# GAP8 register map
Vendor: GreenWaves Technologies SAS; Series: GAP8; File version: 1.3.1
CPU: other r1p0, little endian, MPU, no FPU, I-cache, DTCM, false interrupt priority bits
Registers are 32-bit, read-write, reset 0x0 unless marked. A register's access mark holds for its fields unless they carry their own. Offsets are from the block's base; [hi:lo] are bit positions; {n}, {i} and the like mark numbered series; 'fields as' and 'values as' point back to an identical list.

## apb_soc_ctrl — SoC control unit
Base 0x1A104000
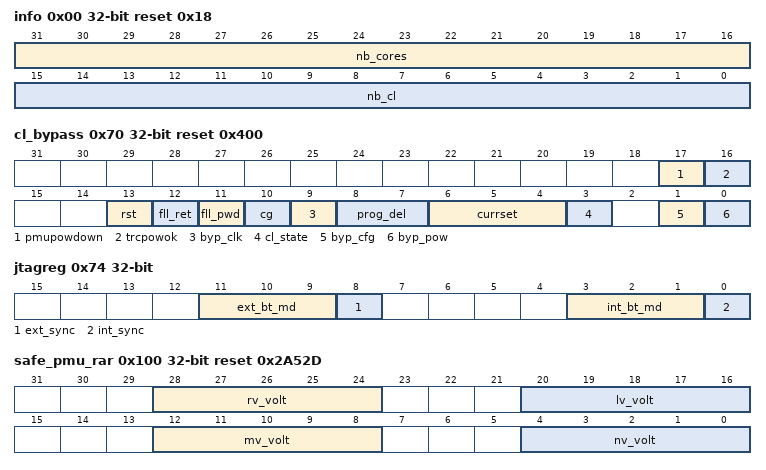
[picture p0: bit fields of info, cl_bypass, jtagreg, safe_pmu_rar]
0x00 info ro reset 0x18 — Core information register
  [31:16] nb_cores — Number of cores
  [15:0] nb_cl — Number of clusters
0x0C cl_isolate reset 0x1 — Isolate cluster register
  [0] en — Isolate cluster. Inhibits AXI transactions from cluster to SoC
    0=disable (feature is disabled); 1=enable (feature is enabled)
0x6C cl_busy ro — Cluster busy register
  [0] busy — Cluster busy flag (i.e. It's 1 if there is at least 1 active block in the cluster)
0x70 cl_bypass reset 0x400 — PMU bypass configuration register
  [17] pmupowdown — Cluster power down from Maestro PMU status bitfield.
  [16] trcpowok — Cluster power ok from cluster TRC status bitfield
  [13] rst — Cluster reset configuration bitfield: - 1’b0: nothing - 1’b1: reset the cluster
  [12] fll_ret — Cluster FLL retentive configuration bitfield: - 1’b0: FLL on - 1’b1: FLL retentive mode
  [11] fll_pwd — Cluster FLL shutdown configuration bitfield: - 1’b0: FLL on - 1’b1: FLL shutdown mode
  [10] cg — Cluster clock gate configuration bitfield: - 1’b0: disabled - 1’b1: enabled It should always be used before switching cluster FLL to shutdown or retentive mode.
  [9] byp_clk — Bypass cluster clock and reset control by Maestro PMU configuration bitfield: - 1’b0: disabled - 1’b1: enabled
  [8:7] prog_del — Number of REFCLK 32kHz after cluster power ok has arised to release TR isolation configuration bitfield.
  [6:4] currset — Max current allowed on cluster TRC configuration bitfield.
  [3] cl_state — Cluster state configuration and status bitfield: - 1’b0: off - 1’b1: on Status information is correct only when bypass mode is enabled.
  [1] byp_cfg — Bypass Maestro PMU configuration selection configuration bitfield: - 1’b0: use default - 1’b1: use user configuration (bitfields from bits 3 to 15 of CL_BYPASS register)
  [0] byp_pow — Bypass Maestro PMU controller configuration bitfield: - 1’b0: disabled - 1’b1: enabled
0x74 jtagreg — JTAG external register
  [11:9] ext_bt_md ro — JTAG external register used for selecting boot mode configuration from external debugger
  [8] ext_sync ro — JTAG external register used for synchronisation from external debugger
  [3:1] int_bt_md — JTAG internal register used for selecting boot mode configuration from external debugger
  [0] int_sync — JTAG internal register used for synchronisation from external debugger
0x78 l2_sleep reset 0x1 — L2 sleep configuration register
  [0] l2_sleep — L2 memory sleep configuration
0x7C sleep_ctrl ro — Alias for SAFE_PMU_SLEEPCTRL
  [31:0] sleep_ctrl — Alias for SAFE_PMU_SLEEPCTRL(i.e. will be accessible in 1 clock cycle)
0xA0 corestatus — EOC and chip status register
  [31:0] status
0xC0 corestatus_ro ro — EOC and chip status register read mirror
  [31:0] status — EOC and chip status register
0x100 safe_pmu_rar reset 0x2A52D — DC/DC configuration register
  [28:24] rv_volt — DC/DC Retentive Voltage setting
  [20:16] lv_volt — DC/DC Low Voltage setting
  [12:8] mv_volt — DC/DC Medium Voltage setting (not used)
  [4:0] nv_volt — DC/DC Nominal Voltage setting
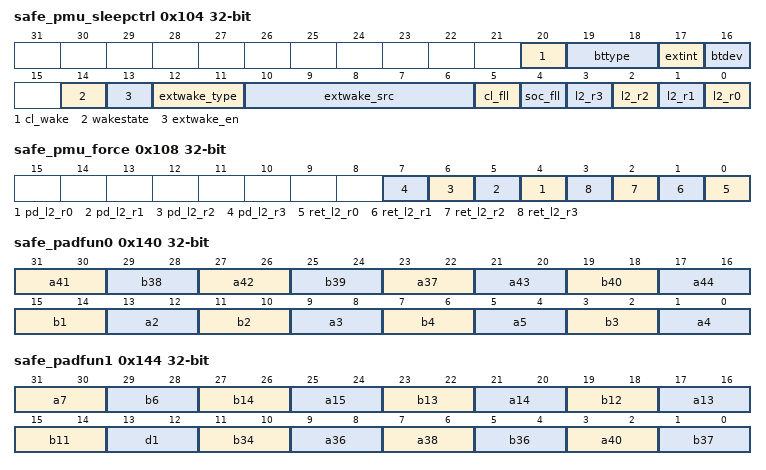
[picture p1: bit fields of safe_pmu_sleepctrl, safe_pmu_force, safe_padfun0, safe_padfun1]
0x104 safe_pmu_sleepctrl — Sleep modes configuration register
  [20] cl_wake — Cluster state to restore after warm boot: - 1’b0: off - 1’b1: on
  [19:18] bttype — Select boot type
    0=cold_boot (set to cold boot); 1=deep_sleep (set to deep sleep); 2=retentive deep sleep
  [17] extint ro — External wake-up interrupt status (automatically resetted after read)
    on read: 0=wake-up triggered by RTC; 1=wake-up triggered by external event
  [16] btdev — Warm bootmode
    0=boot_from_rom (set to Boot from ROM); 1=boot_from_l2 (set to Boot from L2)
  [14] wakestate — Power state to restore after warm boot
    0=soc_lv (set to SoC_LV); 1=soc_hv (set to SoC_HV)
  [13] extwake_en — Enable external wake-up; - 1'b0; external wake-up disabled
    1=external wake-up enabled
  [12:11] extwake_type — Select external wake-up mode
    0=rise_event (set to rise event); 1=fall_event (set to fall event); 2=high_level (set to high level); 3=low_level (set to low level)
  [10:6] extwake_src — Select external wake-up source (GPIO ID)
    {v}=gpio_{v} (set to GPIO {v}) (v=0..31)
  [5] cl_fll — Configure retention mode for cluster FLL
    0=non_retentive (set to Non retentive); 1=retentive (set to Retentive)
  [4] soc_fll — Configure retention mode for SoC FLL
    values as cl_fll
  [n] l2_r{n} (n=0..3) — Configure retention mode for region {n} of L2 memory
    values as cl_fll
0x108 safe_pmu_force — L2 rententive state configuration
  [n+4] pd_l2_r{n} (n=0..3) — Force power down on region {n} of L2 memory: 1'b0: power up 1'b1: power down
  [n] ret_l2_r{n} (n=0..3) — Force retentive state on region {n} of L2 memory: 1'b0: not state retentive 1'b1: state retentive
0x140 safe_padfun0 — Mux config register (pad 0-15)
  [31:30] a41 — Configure [A41](#pin_a41) functionality
    0=alternate_0 (CAM_DATA3 (default)); 1=alternate_1 (GPIOA9); 2=alternate_2 (TIMER2_CH1); 3=alternate_3_- (set to Alternate 3 -)
  [29:28] b38 — Configure [B38](#pin_b38) functionality
    0=alternate_0 (CAM_DATA2 (default)); 1=alternate_1 (GPIOA8); 2=alternate_2 (TIMER2_CH0); 3=alternate_3_- (set to Alternate 3 -)
  [27:26] a42 — Configure [A42](#pin_a42) functionality
    0=alternate_0 (CAM_DATA1 (default)); 1=alternate_1 (GPIOA7); 2=alternate_2 (TIMER1_CH3); 3=alternate_3_- (set to Alternate 3 -)
  [25:24] b39 — Configure [B39](#pin_b39) functionality
    0=alternate_0 (CAM_DATA0 (default)); 1=alternate_1 (GPIOA6); 2=alternate_2 (TIMER1_CH2); 3=alternate_3_- (set to Alternate 3 -)
  [23:22] a37 — Configure [A37](#pin_a37) functionality
    0=alternate_0 (CAM_HSYNC (default)); 1=alternate_1 (GPIOA5); 2=alternate_2 (TIMER1_CH1); 3=alternate_3_- (set to Alternate 3 -)
  [21:20] a43 — Configure [A43](#pin_a43) functionality
    0=alternate_0 (CAM_PCLK (default)); 1=alternate_1 (GPIOA4); 2=alternate_2 (TIMER1_CH0); 3=alternate_3_- (set to Alternate 3 -)
  [19:18] b40 — Configure [B40](#pin_b40) functionality
    0=alternate_0 (ORCA_RXQ (default)); 1=alternate_1 (GPIOA5); 2=alternate_2 (SPIS0_SDIO1); 3=alternate_3 (SPIS0_SDIO3)
  [17:16] a44 — Configure [A44](#pin_a44) functionality
    0=alternate_0 (ORCA_RXI (default)); 1=alternate_1 (GPIOA4); 2=alternate_2 (SPIS0_SDIO0); 3=alternate_3 (SPIS0_SDIO2)
  [15:14] b1 — Configure [B1](#pin_b1) functionality
    0=alternate_0 (ORCA_TXQ (default)); 1=alternate_1 (GPIOA3); 2=alternate_2_- (set to Alternate 2 -); 3=alternate_3_- (set to Alternate 3 -)
  [13:12] a2 — Configure [A2](#pin_a2) functionality
    0=alternate_0 (ORCA_TXI (default)); 1=alternate_1 (GPIOA2); 2=alternate_2_- (set to Alternate 2 -); 3=alternate_3_- (set to Alternate 3 -)
  [11:10] b2 — Configure [B2](#pin_b2) functionality
    0=alternate_0 (ORCA_RXSYNC (default)); 1=alternate_1 (GPIOA1); 2=alternate_2 (SPIM1_CS1); 3=alternate_3_- (set to Alternate 3 -)
  [9:8] a3 — Configure [A3](#pin_a3) functionality
    0=alternate_0 (ORCA_TXSYNC (default)); 1=alternate_1 (GPIOA0); 2=alternate_2 (SPIM1_CS0); 3=alternate_3_- (set to Alternate 3 -)
  [7:6] b4 — Configure [B4](#pin_b4) functionality
    0=alternate_0 (SPIM1_SCK (default)); 1=alternate_1 (GPIOA3); 2=alternate_2 (I2C1_SCL); 3=alternate_3_- (set to Alternate 3 -)
  [5:4] a5 — Configure [A5](#pin_a5) functionality
    0=alternate_0 (SPIM1_CS0 (default)); 1=alternate_1 (GPIOA2); 2=alternate_2 (I2C1_SDA); 3=alternate_3_- (set to Alternate 3 -)
  [3:2] b3 — Configure [B3](#pin_b3) functionality
    0=alternate_0 (SPIM1_MOSI (default)); 1=alternate_1 (GPIOA1); 2=alternate_2_- (set to Alternate 2 -); 3=alternate_3_- (set to Alternate 3 -)
  [1:0] a4 — Configure [A4](#pin_a4) functionality
    0=alternate_0 (SPIM1_MISO (default)); 1=alternate_1 (GPIOA0); 2=alternate_2_- (set to Alternate 2 -); 3=alternate_3_- (set to Alternate 3 -)
0x144 safe_padfun1 — Mux config register (pad 16-31)
  [31:30] a7 — Configure [A7](#pin_a7) functionality
    0=alternate_0 (UART_TX (default)); 1=alternate_1 (GPIOA25); 2=alternate_2_- (set to Alternate 2 -); 3=alternate_3_- (set to Alternate 3 -)
  [29:28] b6 — Configure [B6](#pin_b6) functionality
    0=alternate_0 (UART_RX (default)); 1=alternate_1 (GPIOA24); 2=alternate_2_- (set to Alternate 2 -); 3=alternate_3_- (set to Alternate 3 -)
  [27:26] b14 — Configure [B14](#pin_b14) functionality
    0=alternate_0 (I2S1_SDI (default)); 1=alternate_1 (GPIOA23); 2=alternate_2 (SPIS0_SDIO2); 3=alternate_3 (HYPER_CK)
  [25:24] a15 — Configure [A15](#pin_a15) functionality
    0=alternate_0 (I2S1_WS (default)); 1=alternate_1 (GPIOA22); 2=alternate_2 (SPIS0_CS); 3=alternate_3 (HYPER_CKN)
  [23:22] b13 — Configure [B13](#pin_b13) functionality
    0=alternate_0 (I2S1_SCK (default)); 1=alternate_1 (GPIOA21); 2=alternate_2 (SPIS0_SCK); 3=alternate_3 (I2S1_SDI)
  [21:20] a14 — Configure [A14](#pin_a14) functionality
    0=alternate_0 (TIMER0_CH3 (default)); 1=alternate_1 (GPIOA20); 2=alternate_2 (TIMER3_CH0); 3=alternate_3_- (set to Alternate 3 -)
  [19:18] b12 — Configure [B12](#pin_b12) functionality
    0=alternate_0 (TIMER0_CH2 (default)); 1=alternate_1 (GPIOA19); 2=alternate_2 (TIMER2_CH0); 3=alternate_3_- (set to Alternate 3 -)
  [17:16] a13 — Configure [A13](#pin_a13) functionality
    0=alternate_0 (TIMER0_CH1 (default)); 1=alternate_1 (GPIOA18); 2=alternate_2 (TIMER1_CH0); 3=alternate_3_- (set to Alternate 3 -)
  [15:14] b11 — Configure [B11](#pin_b11) functionality
    0=alternate_0 (TIMER0_CH0 (default)); 1=alternate_1 (GPIOA17); 2=alternate_2_- (set to Alternate 2 -); 3=alternate_3_- (set to Alternate 3 -)
  [13:12] d1 — Configure [D1](#pin_d1) functionality
    0=alternate_0 (I2C1_SCL (default)); 1=alternate_1 (GPIOA16); 2=alternate_2 (ORCA_CLK); 3=alternate_3_- (set to Alternate 3 -)
  [11:10] b34 — Configure [B34](#pin_b34) functionality
    0=alternate_0 (I2C1_SDA (default)); 1=alternate_1 (GPIOA15); 2=alternate_2 (TIMER3_CH3); 3=alternate_3_- (set to Alternate 3 -)
  [9:8] a36 — Configure [A36](#pin_a36) functionality
    0=alternate_0 (CAM_VSYNC (default)); 1=alternate_1 (GPIOA14); 2=alternate_2 (TIMER3_CH2); 3=alternate_3_- (set to Alternate 3 -)
  [7:6] a38 — Configure [A38](#pin_a38) functionality
    0=alternate_0 (CAM_DATA7 (default)); 1=alternate_1 (GPIOA13); 2=alternate_2 (TIMER3_CH1); 3=alternate_3_- (set to Alternate 3 -)
  [5:4] b36 — Configure [B36](#pin_b36) functionality
    0=alternate_0 (CAM_DATA6 (default)); 1=alternate_1 (GPIOA12); 2=alternate_2 (TIMER3_CH0); 3=alternate_3_- (set to Alternate 3 -)
  [3:2] a40 — Configure [A40](#pin_a40) functionality
    0=alternate_0 (CAM_DATA5 (default)); 1=alternate_1 (GPIOA11); 2=alternate_2 (TIMER2_CH3); 3=alternate_3_- (set to Alternate 3 -)
  [1:0] b37 — Configure [B37](#pin_b37) functionality
    0=alternate_0 (CAM_DATA4 (default)); 1=alternate_1 (GPIOA10); 2=alternate_2 (TIMER2_CH2); 3=alternate_3_- (set to Alternate 3 -)
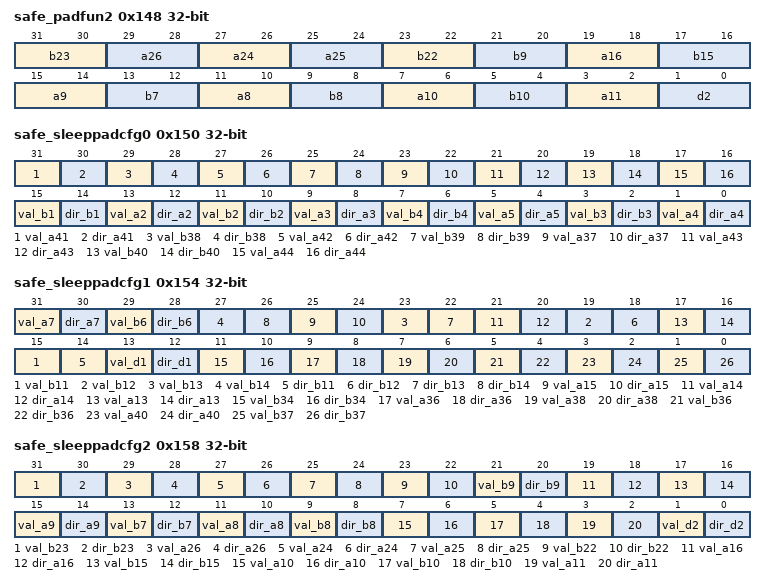
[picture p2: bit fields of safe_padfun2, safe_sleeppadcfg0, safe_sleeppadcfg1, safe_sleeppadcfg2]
0x148 safe_padfun2 — Mux config register (pad 32-47)
  [31:30] b23 — Configure [B23](#pin_b23) functionality
    0=alternate_0 (I2S0_SDI (default)); 1=alternate_1_- (set to Alternate 1 -); 2=alternate_2_- (set to Alternate 2 -); 3=alternate_3_- (set to Alternate 3 -)
  [29:28] a26 — Configure [A26](#pin_a26) functionality
    0=alternate_0 (I2S0_WS (default)); 1=alternate_1_- (set to Alternate 1 -); 2=alternate_2_- (set to Alternate 2 -); 3=alternate_3_- (set to Alternate 3 -)
  [27:26] a24 — Configure [A24](#pin_a24) functionality
    0=alternate_0 (I2S0_SCK (default)); 1=alternate_1_- (set to Alternate 1 -); 2=alternate_2_- (set to Alternate 2 -); 3=alternate_3_- (set to Alternate 3 -)
  [25:24] a25 — Configure [A25](#pin_a25) functionality
    0=alternate_0 (I2C0_SCL (default)); 1=alternate_1_- (set to Alternate 1 -); 2=alternate_2_- (set to Alternate 2 -); 3=alternate_3_- (set to Alternate 3 -)
  [23:22] b22 — Configure [B22](#pin_b22) functionality
    0=alternate_0 (I2C0_SDA (default)); 1=alternate_1_- (set to Alternate 1 -); 2=alternate_2_- (set to Alternate 2 -); 3=alternate_3_- (set to Alternate 3 -)
  [21:20] b9 — Configure [B9](#pin_b9) functionality
    0=alternate_0 (SPIS0_SCK (default)); 1=alternate_1_- (set to Alternate 1 -); 2=alternate_2_- (set to Alternate 2 -); 3=alternate_3 (HYPER_RWDS)
  [19:18] a16 — Configure [A16](#pin_a16) functionality
    0=alternate_0 (SPIS0_SDIO1 (default)); 1=alternate_1 (GPIOA31); 2=alternate_2_- (set to Alternate 2 -); 3=alternate_3 (HYPER_CSN1)
  [17:16] b15 — Configure [B15](#pin_b15) functionality
    0=alternate_0 (SPIS0_SDIO0 (default)); 1=alternate_1 (GPIOA30); 2=alternate_2 (SPIM1_CS1); 3=alternate_3 (HYPER_CSN0)
  [15:14] a9 — Configure [A9](#pin_a9) functionality
    0=alternate_0 (SPIS0_CS (default)); 1=alternate_1 (GPIOA29); 2=alternate_2 (SPIM1_CS0); 3=alternate_3 (HYPER_DQ[7])
  [13:12] b7 — Configure [B7](#pin_b7) functionality
    0=alternate_0 (SPIM0_SCK (default)); 1=alternate_1_- (set to Alternate 1 -); 2=alternate_2_- (set to Alternate 2 -); 3=alternate_3 (HYPER_DQ[6])
  [11:10] a8 — Configure [A8](#pin_a8) functionality
    0=alternate_0 (SPIM0_CS1 (default)); 1=alternate_1 (GPIOA28); 2=alternate_2 (SPIS0_SDIO3); 3=alternate_3 (HYPER_DQ[5])
  [9:8] b8 — Configure [B8](#pin_b8) functionality
    0=alternate_0 (SPIM0_CS0 (default)); 1=alternate_1_- (set to Alternate 1 -); 2=alternate_2_- (set to Alternate 2 -); 3=alternate_3 (HYPER_DQ[4])
  [7:6] a10 — Configure [A10](#pin_a10) functionality
    0=alternate_0 (SPIM0_SDIO3 (default)); 1=alternate_1 (GPIOA27); 2=alternate_2 (I2C1_SCL); 3=alternate_3 (HYPER_DQ[3])
  [5:4] b10 — Configure [B10](#pin_b10) functionality
    0=alternate_0 (SPIM0_SDIO2 (default)); 1=alternate_1 (GPIOA26); 2=alternate_2 (I2C1_SDA); 3=alternate_3 (HYPER_DQ[2])
  [3:2] a11 — Configure [A11](#pin_a11) functionality
    0=alternate_0 (SPIM0_SDIO1 (default)); 1=alternate_1_- (set to Alternate 1 -); 2=alternate_2_- (set to Alternate 2 -); 3=alternate_3 (HYPER_DQ[1])
  [1:0] d2 — Configure [D2](#pin_d2) functionality
    0=alternate_0 (SPIM0_SDIO0 (default)); 1=alternate_1_- (set to Alternate 1 -); 2=alternate_2_- (set to Alternate 2 -); 3=alternate_3 (HYPER_DQ[0])
0x150 safe_sleeppadcfg0 — Sleep config register (pad 0-15)
  [31] val_a41 — Select [A41](#pin_a41) sleep state
    0=Input or output low; 1=Input or output high
  [30] dir_a41 — Select [A41](#pin_a41) sleep direction
    0=input (direction is input); 1=output (direction is output)
  [29] val_b38 — Select [B38](#pin_b38) sleep state
    0=Input or output low; 1=Input or output high
  [28] dir_b38 — Select [B38](#pin_b38) sleep direction
    0=input (direction is input); 1=output (direction is output)
  [27] val_a42 — Select [A42](#pin_a42) sleep state
    0=Input or output low; 1=Input or output high
  [26] dir_a42 — Select [A42](#pin_a42) sleep direction
    0=input (direction is input); 1=output (direction is output)
  [25] val_b39 — Select [B39](#pin_b39) sleep state
    0=Input or output low; 1=Input or output high
  [24] dir_b39 — Select [B39](#pin_b39) sleep direction
    0=input (direction is input); 1=output (direction is output)
  [23] val_a37 — Select [A37](#pin_a37) sleep state
    0=Input or output low; 1=Input or output high
  [22] dir_a37 — Select [A37](#pin_a37) sleep direction
    0=input (direction is input); 1=output (direction is output)
  [21] val_a43 — Select [A43](#pin_a43) sleep state
    0=Input or output low; 1=Input or output high
  [20] dir_a43 — Select [A43](#pin_a43) sleep direction
    0=input (direction is input); 1=output (direction is output)
  [19] val_b40 — Select [B40](#pin_b40) sleep state
    0=Input or output low; 1=Input or output high
  [18] dir_b40 — Select [B40](#pin_b40) sleep direction
    0=input (direction is input); 1=output (direction is output)
  [17] val_a44 — Select [A44](#pin_a44) sleep state
    0=Input or output low; 1=Input or output high
  [16] dir_a44 — Select [A44](#pin_a44) sleep direction
    0=input (direction is input); 1=output (direction is output)
  [15] val_b1 — Select [B1](#pin_b1) sleep state
    0=Input or output low; 1=Input or output high
  [14] dir_b1 — Select [B1](#pin_b1) sleep direction
    0=input (direction is input); 1=output (direction is output)
  [13] val_a2 — Select [A2](#pin_a2) sleep state
    0=Input or output low; 1=Input or output high
  [12] dir_a2 — Select [A2](#pin_a2) sleep direction
    0=input (direction is input); 1=output (direction is output)
  [11] val_b2 — Select [B2](#pin_b2) sleep state
    0=Input or output low; 1=Input or output high
  [10] dir_b2 — Select [B2](#pin_b2) sleep direction
    0=input (direction is input); 1=output (direction is output)
  [9] val_a3 — Select [A3](#pin_a3) sleep state
    0=Input or output low; 1=Input or output high
  [8] dir_a3 — Select [A3](#pin_a3) sleep direction
    0=input (direction is input); 1=output (direction is output)
  [7] val_b4 — Select [B4](#pin_b4) sleep state
    0=Input or output low; 1=Input or output high
  [6] dir_b4 — Select [B4](#pin_b4) sleep direction
    0=input (direction is input); 1=output (direction is output)
  [5] val_a5 — Select [A5](#pin_a5) sleep state
    0=Input or output low; 1=Input or output high
  [4] dir_a5 — Select [A5](#pin_a5) sleep direction
    0=input (direction is input); 1=output (direction is output)
  [3] val_b3 — Select [B3](#pin_b3) sleep state
    0=Input or output low; 1=Input or output high
  [2] dir_b3 — Select [B3](#pin_b3) sleep direction
    0=input (direction is input); 1=output (direction is output)
  [1] val_a4 — Select [A4](#pin_a4) sleep state
    0=Input or output low; 1=Input or output high
  [0] dir_a4 — Select [A4](#pin_a4) sleep direction
    0=input (direction is input); 1=output (direction is output)
0x154 safe_sleeppadcfg1 — Mux config register (pad 16-31)
  [31] val_a7 — Select [A7](#pin_a7) sleep state
    0=Input or output low; 1=Input or output high
  [30] dir_a7 — Select [A7](#pin_a7) sleep direction
    0=input (direction is input); 1=output (direction is output)
  [29] val_b6 — Select [B6](#pin_b6) sleep state
    0=Input or output low; 1=Input or output high
  [28] dir_b6 — Select [B6](#pin_b6) sleep direction
    0=input (direction is input); 1=output (direction is output)
  [4n-29] val_b{n} (n=11..14) — Select [B{n}](#pin_b{n}) sleep state
    0=Input or output low; 1=Input or output high
  [4n-30] dir_b{n} (n=11..14) — Select [B{n}](#pin_b{n}) sleep direction
    0=input (direction is input); 1=output (direction is output)
  [25] val_a15 — Select [A15](#pin_a15) sleep state
    0=Input or output low; 1=Input or output high
  [24] dir_a15 — Select [A15](#pin_a15) sleep direction
    0=input (direction is input); 1=output (direction is output)
  [21] val_a14 — Select [A14](#pin_a14) sleep state
    0=Input or output low; 1=Input or output high
  [20] dir_a14 — Select [A14](#pin_a14) sleep direction
    0=input (direction is input); 1=output (direction is output)
  [17] val_a13 — Select [A13](#pin_a13) sleep state
    0=Input or output low; 1=Input or output high
  [16] dir_a13 — Select [A13](#pin_a13) sleep direction
    0=input (direction is input); 1=output (direction is output)
  [13] val_d1 — Select [D1](#pin_d1) sleep state
    0=Input or output low; 1=Input or output high
  [12] dir_d1 — Select [D1](#pin_d1) sleep direction
    0=input (direction is input); 1=output (direction is output)
  [11] val_b34 — Select [B34](#pin_b34) sleep state
    0=Input or output low; 1=Input or output high
  [10] dir_b34 — Select [B34](#pin_b34) sleep direction
    0=input (direction is input); 1=output (direction is output)
  [9] val_a36 — Select [A36](#pin_a36) sleep state
    0=Input or output low; 1=Input or output high
  [8] dir_a36 — Select [A36](#pin_a36) sleep direction
    0=input (direction is input); 1=output (direction is output)
  [7] val_a38 — Select [A38](#pin_a38) sleep state
    0=Input or output low; 1=Input or output high
  [6] dir_a38 — Select [A38](#pin_a38) sleep direction
    0=input (direction is input); 1=output (direction is output)
  [5] val_b36 — Select [B36](#pin_b36) sleep state
    0=Input or output low; 1=Input or output high
  [4] dir_b36 — Select [B36](#pin_b36) sleep direction
    0=input (direction is input); 1=output (direction is output)
  [3] val_a40 — Select [A40](#pin_a40) sleep state
    0=Input or output low; 1=Input or output high
  [2] dir_a40 — Select [A40](#pin_a40) sleep direction
    0=input (direction is input); 1=output (direction is output)
  [1] val_b37 — Select [B37](#pin_b37) sleep state
    0=Input or output low; 1=Input or output high
  [0] dir_b37 — Select [B37](#pin_b37) sleep direction
    0=input (direction is input); 1=output (direction is output)
0x158 safe_sleeppadcfg2 — Mux config register (pad 32-47)
  [31] val_b23 — Select [B23](#pin_b23) sleep state
    0=Input or output low; 1=Input or output high
  [30] dir_b23 — Select [B23](#pin_b23) sleep direction
    0=input (direction is input); 1=output (direction is output)
  [29] val_a26 — Select [A26](#pin_a26) sleep state
    0=Input or output low; 1=Input or output high
  [28] dir_a26 — Select [A26](#pin_a26) sleep direction
    0=input (direction is input); 1=output (direction is output)
  [27] val_a24 — Select [A24](#pin_a24) sleep state
    0=Input or output low; 1=Input or output high
  [26] dir_a24 — Select [A24](#pin_a24) sleep direction
    0=input (direction is input); 1=output (direction is output)
  [25] val_a25 — Select [A25](#pin_a25) sleep state
    0=Input or output low; 1=Input or output high
  [24] dir_a25 — Select [A25](#pin_a25) sleep direction
    0=input (direction is input); 1=output (direction is output)
  [23] val_b22 — Select [B22](#pin_b22) sleep state
    0=Input or output low; 1=Input or output high
  [22] dir_b22 — Select [B22](#pin_b22) sleep direction
    0=input (direction is input); 1=output (direction is output)
  [21] val_b9 — Select [B9](#pin_b9) sleep state
    0=Input or output low; 1=Input or output high
  [20] dir_b9 — Select [B9](#pin_b9) sleep direction
    0=input (direction is input); 1=output (direction is output)
  [19] val_a16 — Select [A16](#pin_a16) sleep state
    0=Input or output low; 1=Input or output high
  [18] dir_a16 — Select [A16](#pin_a16) sleep direction
    0=input (direction is input); 1=output (direction is output)
  [17] val_b15 — Select [B15](#pin_b15) sleep state
    0=Input or output low; 1=Input or output high
  [16] dir_b15 — Select [B15](#pin_b15) sleep direction
    0=input (direction is input); 1=output (direction is output)
  [15] val_a9 — Select [A9](#pin_a9) sleep state
    0=Input or output low; 1=Input or output high
  [14] dir_a9 — Select [A9](#pin_a9) sleep direction
    0=input (direction is input); 1=output (direction is output)
  [13] val_b7 — Select [B7](#pin_b7) sleep state
    0=Input or output low; 1=Input or output high
  [12] dir_b7 — Select [B7](#pin_b7) sleep direction
    0=input (direction is input); 1=output (direction is output)
  [11] val_a8 — Select [A8](#pin_a8) sleep state
    0=Input or output low; 1=Input or output high
  [10] dir_a8 — Select [A8](#pin_a8) sleep direction
    0=input (direction is input); 1=output (direction is output)
  [9] val_b8 — Select [B8](#pin_b8) sleep state
    0=Input or output low; 1=Input or output high
  [8] dir_b8 — Select [B8](#pin_b8) sleep direction
    0=input (direction is input); 1=output (direction is output)
  [7] val_a10 — Select [A10](#pin_a10) sleep state
    0=Input or output low; 1=Input or output high
  [6] dir_a10 — Select [A10](#pin_a10) sleep direction
    0=input (direction is input); 1=output (direction is output)
  [5] val_b10 — Select [B10](#pin_b10) sleep state
    0=Input or output low; 1=Input or output high
  [4] dir_b10 — Select [B10](#pin_b10) sleep direction
    0=input (direction is input); 1=output (direction is output)
  [3] val_a11 — Select [A11](#pin_a11) sleep state
    0=Input or output low; 1=Input or output high
  [2] dir_a11 — Select [A11](#pin_a11) sleep direction
    0=input (direction is input); 1=output (direction is output)
  [1] val_d2 — Select [D2](#pin_d2) sleep state
    0=Input or output low; 1=Input or output high
  [0] dir_d2 — Select [D2](#pin_d2) sleep direction
    0=input (direction is input); 1=output (direction is output)
0x160 safe_padsleep — Enable Sleep mode for pads
  [0] en — Enable pad sleep mode: 1'b0: disable 1'b1: enable
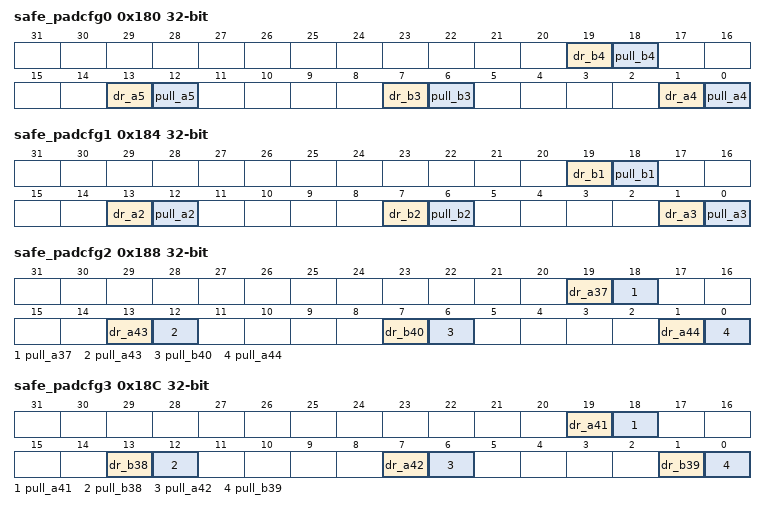
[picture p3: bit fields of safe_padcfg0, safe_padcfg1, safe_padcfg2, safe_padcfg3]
0x180 safe_padcfg0 — Function register (pad 0 to 3)
  [19] dr_b4 — Select [B4](#pin_b4) drive strength
    0=low_drive_strength (set to low drive strength); 1=high drive strength
  [18] pull_b4 — Select [B4](#pin_b4) pull activation
    0=pull_disabled (set to pull disabled); 1=pull_enabled (set to pull enabled)
  [13] dr_a5 — Select [A5](#pin_a5) drive strength
    values as dr_b4
  [12] pull_a5 — Select [A5](#pin_a5) pull activation
    values as pull_b4
  [7] dr_b3 — Select [B3](#pin_b3) drive strength
    values as dr_b4
  [6] pull_b3 — Select [B3](#pin_b3) pull activation
    values as pull_b4
  [1] dr_a4 — Select [A4](#pin_a4) drive strength
    values as dr_b4
  [0] pull_a4 — Select [A4](#pin_a4) pull activation
    values as pull_b4
0x184 safe_padcfg1 — Function register (pad 4 to 7)
  [19] dr_b1 — Select [B1](#pin_b1) drive strength
    values as safe_padcfg0.dr_b4
  [18] pull_b1 — Select [B1](#pin_b1) pull activation
    values as safe_padcfg0.pull_b4
  [13] dr_a2 — Select [A2](#pin_a2) drive strength
    values as safe_padcfg0.dr_b4
  [12] pull_a2 — Select [A2](#pin_a2) pull activation
    values as safe_padcfg0.pull_b4
  [7] dr_b2 — Select [B2](#pin_b2) drive strength
    values as safe_padcfg0.dr_b4
  [6] pull_b2 — Select [B2](#pin_b2) pull activation
    values as safe_padcfg0.pull_b4
  [1] dr_a3 — Select [A3](#pin_a3) drive strength
    values as safe_padcfg0.dr_b4
  [0] pull_a3 — Select [A3](#pin_a3) pull activation
    values as safe_padcfg0.pull_b4
0x188 safe_padcfg2 — Function register (pad 8 to 11)
  [19] dr_a37 — Select [A37](#pin_a37) drive strength
    values as safe_padcfg0.dr_b4
  [18] pull_a37 — Select [A37](#pin_a37) pull activation
    values as safe_padcfg0.pull_b4
  [13] dr_a43 — Select [A43](#pin_a43) drive strength
    values as safe_padcfg0.dr_b4
  [12] pull_a43 — Select [A43](#pin_a43) pull activation
    values as safe_padcfg0.pull_b4
  [7] dr_b40 — Select [B40](#pin_b40) drive strength
    values as safe_padcfg0.dr_b4
  [6] pull_b40 — Select [B40](#pin_b40) pull activation
    values as safe_padcfg0.pull_b4
  [1] dr_a44 — Select [A44](#pin_a44) drive strength
    values as safe_padcfg0.dr_b4
  [0] pull_a44 — Select [A44](#pin_a44) pull activation
    values as safe_padcfg0.pull_b4
0x18C safe_padcfg3 — Function register (pad 12 to 15)
  [19] dr_a41 — Select [A41](#pin_a41) drive strength
    values as safe_padcfg0.dr_b4
  [18] pull_a41 — Select [A41](#pin_a41) pull activation
    values as safe_padcfg0.pull_b4
  [13] dr_b38 — Select [B38](#pin_b38) drive strength
    values as safe_padcfg0.dr_b4
  [12] pull_b38 — Select [B38](#pin_b38) pull activation
    values as safe_padcfg0.pull_b4
  [7] dr_a42 — Select [A42](#pin_a42) drive strength
    values as safe_padcfg0.dr_b4
  [6] pull_a42 — Select [A42](#pin_a42) pull activation
    values as safe_padcfg0.pull_b4
  [1] dr_b39 — Select [B39](#pin_b39) drive strength
    values as safe_padcfg0.dr_b4
  [0] pull_b39 — Select [B39](#pin_b39) pull activation
    values as safe_padcfg0.pull_b4
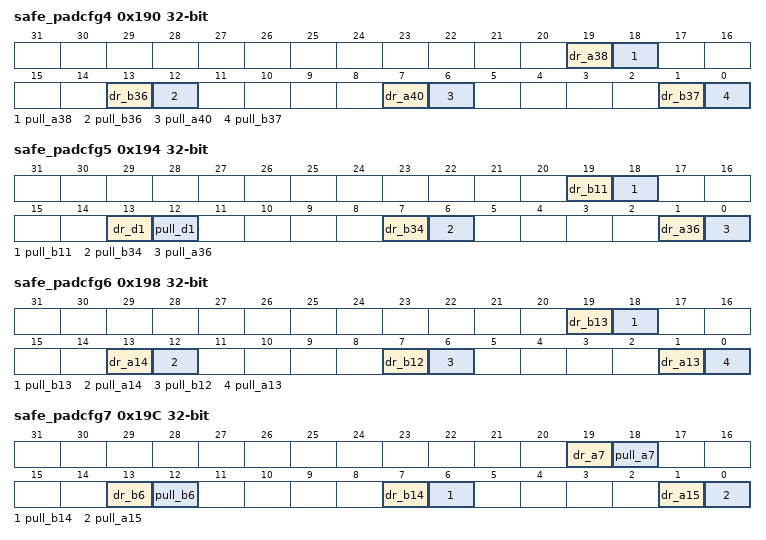
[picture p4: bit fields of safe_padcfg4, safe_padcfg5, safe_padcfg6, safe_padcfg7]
0x190 safe_padcfg4 — Function register (pad 16 to 19)
  [19] dr_a38 — Select [A38](#pin_a38) drive strength
    values as safe_padcfg0.dr_b4
  [18] pull_a38 — Select [A38](#pin_a38) pull activation
    values as safe_padcfg0.pull_b4
  [13] dr_b36 — Select [B36](#pin_b36) drive strength
    values as safe_padcfg0.dr_b4
  [12] pull_b36 — Select [B36](#pin_b36) pull activation
    values as safe_padcfg0.pull_b4
  [7] dr_a40 — Select [A40](#pin_a40) drive strength
    values as safe_padcfg0.dr_b4
  [6] pull_a40 — Select [A40](#pin_a40) pull activation
    values as safe_padcfg0.pull_b4
  [1] dr_b37 — Select [B37](#pin_b37) drive strength
    values as safe_padcfg0.dr_b4
  [0] pull_b37 — Select [B37](#pin_b37) pull activation
    values as safe_padcfg0.pull_b4
0x194 safe_padcfg5 — Function register (pad 20 to 23)
  [19] dr_b11 — Select [B11](#pin_b11) drive strength
    values as safe_padcfg0.dr_b4
  [18] pull_b11 — Select [B11](#pin_b11) pull activation
    values as safe_padcfg0.pull_b4
  [13] dr_d1 — Select [D1](#pin_d1) drive strength
    values as safe_padcfg0.dr_b4
  [12] pull_d1 — Select [D1](#pin_d1) pull activation
    values as safe_padcfg0.pull_b4
  [7] dr_b34 — Select [B34](#pin_b34) drive strength
    values as safe_padcfg0.dr_b4
  [6] pull_b34 — Select [B34](#pin_b34) pull activation
    values as safe_padcfg0.pull_b4
  [1] dr_a36 — Select [A36](#pin_a36) drive strength
    values as safe_padcfg0.dr_b4
  [0] pull_a36 — Select [A36](#pin_a36) pull activation
    values as safe_padcfg0.pull_b4
0x198 safe_padcfg6 — Function register (pad 24 to 27)
  [19] dr_b13 — Select [B13](#pin_b13) drive strength
    values as safe_padcfg0.dr_b4
  [18] pull_b13 — Select [B13](#pin_b13) pull activation
    values as safe_padcfg0.pull_b4
  [13] dr_a14 — Select [A14](#pin_a14) drive strength
    values as safe_padcfg0.dr_b4
  [12] pull_a14 — Select [A14](#pin_a14) pull activation
    values as safe_padcfg0.pull_b4
  [7] dr_b12 — Select [B12](#pin_b12) drive strength
    values as safe_padcfg0.dr_b4
  [6] pull_b12 — Select [B12](#pin_b12) pull activation
    values as safe_padcfg0.pull_b4
  [1] dr_a13 — Select [A13](#pin_a13) drive strength
    values as safe_padcfg0.dr_b4
  [0] pull_a13 — Select [A13](#pin_a13) pull activation
    values as safe_padcfg0.pull_b4
0x19C safe_padcfg7 — Function register (pad 28 to 31)
  [19] dr_a7 — Select [A7](#pin_a7) drive strength
    values as safe_padcfg0.dr_b4
  [18] pull_a7 — Select [A7](#pin_a7) pull activation
    values as safe_padcfg0.pull_b4
  [13] dr_b6 — Select [B6](#pin_b6) drive strength
    values as safe_padcfg0.dr_b4
  [12] pull_b6 — Select [B6](#pin_b6) pull activation
    values as safe_padcfg0.pull_b4
  [7] dr_b14 — Select [B14](#pin_b14) drive strength
    values as safe_padcfg0.dr_b4
  [6] pull_b14 — Select [B14](#pin_b14) pull activation
    values as safe_padcfg0.pull_b4
  [1] dr_a15 — Select [A15](#pin_a15) drive strength
    values as safe_padcfg0.dr_b4
  [0] pull_a15 — Select [A15](#pin_a15) pull activation
    values as safe_padcfg0.pull_b4
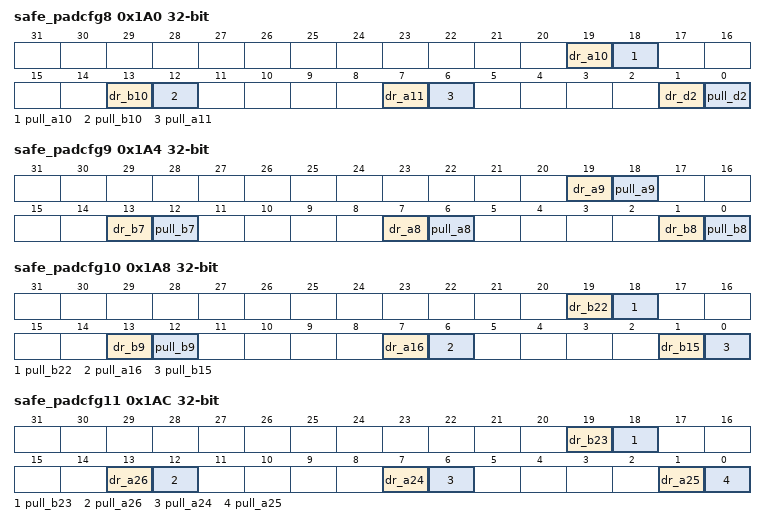
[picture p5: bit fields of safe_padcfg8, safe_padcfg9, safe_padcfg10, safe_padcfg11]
0x1A0 safe_padcfg8 — Function register (pad 32 to 35)
  [19] dr_a10 — Select [A10](#pin_a10) drive strength
    values as safe_padcfg0.dr_b4
  [18] pull_a10 — Select [A10](#pin_a10) pull activation
    values as safe_padcfg0.pull_b4
  [13] dr_b10 — Select [B10](#pin_b10) drive strength
    values as safe_padcfg0.dr_b4
  [12] pull_b10 — Select [B10](#pin_b10) pull activation
    values as safe_padcfg0.pull_b4
  [7] dr_a11 — Select [A11](#pin_a11) drive strength
    values as safe_padcfg0.dr_b4
  [6] pull_a11 — Select [A11](#pin_a11) pull activation
    values as safe_padcfg0.pull_b4
  [1] dr_d2 — Select [D2](#pin_d2) drive strength
    values as safe_padcfg0.dr_b4
  [0] pull_d2 — Select [D2](#pin_d2) pull activation
    values as safe_padcfg0.pull_b4
0x1A4 safe_padcfg9 — Function register (pad 36 to 39)
  [19] dr_a9 — Select [A9](#pin_a9) drive strength
    values as safe_padcfg0.dr_b4
  [18] pull_a9 — Select [A9](#pin_a9) pull activation
    values as safe_padcfg0.pull_b4
  [13] dr_b7 — Select [B7](#pin_b7) drive strength
    values as safe_padcfg0.dr_b4
  [12] pull_b7 — Select [B7](#pin_b7) pull activation
    values as safe_padcfg0.pull_b4
  [7] dr_a8 — Select [A8](#pin_a8) drive strength
    values as safe_padcfg0.dr_b4
  [6] pull_a8 — Select [A8](#pin_a8) pull activation
    values as safe_padcfg0.pull_b4
  [1] dr_b8 — Select [B8](#pin_b8) drive strength
    values as safe_padcfg0.dr_b4
  [0] pull_b8 — Select [B8](#pin_b8) pull activation
    values as safe_padcfg0.pull_b4
0x1A8 safe_padcfg10 — Function register (pad 40 to 43)
  [19] dr_b22 — Select [B22](#pin_b22) drive strength
    values as safe_padcfg0.dr_b4
  [18] pull_b22 — Select [B22](#pin_b22) pull activation
    values as safe_padcfg0.pull_b4
  [13] dr_b9 — Select [B9](#pin_b9) drive strength
    values as safe_padcfg0.dr_b4
  [12] pull_b9 — Select [B9](#pin_b9) pull activation
    values as safe_padcfg0.pull_b4
  [7] dr_a16 — Select [A16](#pin_a16) drive strength
    values as safe_padcfg0.dr_b4
  [6] pull_a16 — Select [A16](#pin_a16) pull activation
    values as safe_padcfg0.pull_b4
  [1] dr_b15 — Select [B15](#pin_b15) drive strength
    values as safe_padcfg0.dr_b4
  [0] pull_b15 — Select [B15](#pin_b15) pull activation
    values as safe_padcfg0.pull_b4
0x1AC safe_padcfg11 — Function register (pad 44 to 47)
  [19] dr_b23 — Select [B23](#pin_b23) drive strength
    values as safe_padcfg0.dr_b4
  [18] pull_b23 — Select [B23](#pin_b23) pull activation
    values as safe_padcfg0.pull_b4
  [13] dr_a26 — Select [A26](#pin_a26) drive strength
    values as safe_padcfg0.dr_b4
  [12] pull_a26 — Select [A26](#pin_a26) pull activation
    values as safe_padcfg0.pull_b4
  [7] dr_a24 — Select [A24](#pin_a24) drive strength
    values as safe_padcfg0.dr_b4
  [6] pull_a24 — Select [A24](#pin_a24) pull activation
    values as safe_padcfg0.pull_b4
  [1] dr_a25 — Select [A25](#pin_a25) drive strength
    values as safe_padcfg0.dr_b4
  [0] pull_a25 — Select [A25](#pin_a25) pull activation
    values as safe_padcfg0.pull_b4
0x1C0 reg_gpio_iso — GPIO power domain pad input isolation register
  [0] iso — Configuration of GPIO domain pads isolation
    0=not_isolated (set to not isolated); 1=isolated (set to isolated)
0x1C4 reg_cam_iso — CAM power domain pad input isolation register
  [0] iso — Configuration of CAM domain pads isolation
    values as reg_gpio_iso.iso
0x1C8 reg_lvds_iso — LVDS power domain pad input isolation register
  [0] iso — Configuration of LVDS domain pads isolation
    values as reg_gpio_iso.iso

## Notices in the file
Copyright (c) 2017 GreenWaves Technologies SAS
All rights reserved.
Redistribution and use in source and binary forms, with or without
modification, are permitted provided that the following conditions are met:
1. Redistributions of source code must retain the above copyright notice,
this list of conditions and the following disclaimer.
2. Redistributions in binary form must reproduce the above copyright
notice, this list of conditions and the following disclaimer in the
documentation and/or other materials provided with the distribution.
3. Neither the name of GreenWaves Technologies SAS nor the names of its
contributors may be used to endorse or promote products derived from
this software without specific prior written permission.
THIS SOFTWARE IS PROVIDED BY THE COPYRIGHT HOLDERS AND CONTRIBUTORS "AS IS"
AND ANY EXPRESS OR IMPLIED WARRANTIES, INCLUDING, BUT NOT LIMITED TO, THE
IMPLIED WARRANTIES OF MERCHANTABILITY AND FITNESS FOR A PARTICULAR PURPOSE
ARE DISCLAIMED. IN NO EVENT SHALL THE COPYRIGHT OWNER OR CONTRIBUTORS BE
LIABLE FOR ANY DIRECT, INDIRECT, INCIDENTAL, SPECIAL, EXEMPLARY, OR
CONSEQUENTIAL DAMAGES (INCLUDING, BUT NOT LIMITED TO, PROCUREMENT OF
SUBSTITUTE GOODS OR SERVICES; LOSS OF USE, DATA, OR PROFITS; OR BUSINESS
INTERRUPTION) HOWEVER CAUSED AND ON ANY THEORY OF LIABILITY, WHETHER IN
CONTRACT, STRICT LIABILITY, OR TORT (INCLUDING NEGLIGENCE OR OTHERWISE)
ARISING IN ANY WAY OUT OF THE USE OF THIS SOFTWARE, EVEN IF ADVISED OF THE
POSSIBILITY OF SUCH DAMAGE.
